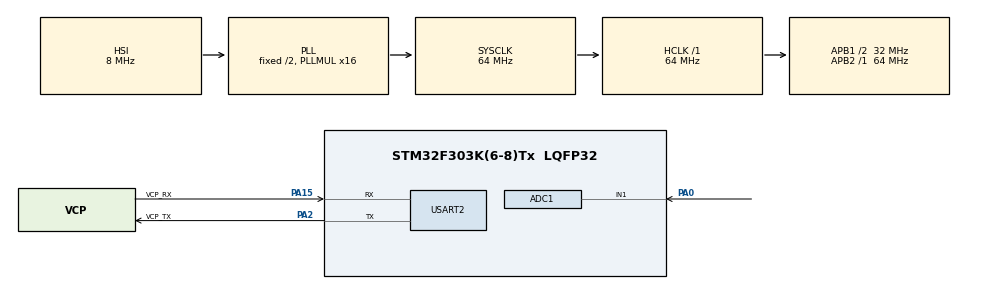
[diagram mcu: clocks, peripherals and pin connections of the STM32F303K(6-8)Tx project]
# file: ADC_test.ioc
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ADC1.Channel-5\#ChannelRegularConversion=ADC_CHANNEL_1
ADC1.ClockPrescaler=ADC_CLOCK_SYNC_PCLK_DIV4
ADC1.NbrOfConversionFlag=1
ADC1.Offset-5\#ChannelRegularConversion=0
ADC1.OffsetNumber-5\#ChannelRegularConversion=ADC_OFFSET_NONE
ADC1.Rank-5\#ChannelRegularConversion=1
ADC1.SamplingTime-5\#ChannelRegularConversion=ADC_SAMPLETIME_1CYCLE_5
ADC1.master=1
Mcu.Family=STM32F3
Mcu.Name=STM32F303K(6-8)Tx
Mcu.Package=LQFP32
NVIC.PriorityGroup=NVIC_PRIORITYGROUP_4
PA0.Mode=IN1-Single-Ended
PA0.Signal=ADC1_IN1
PA13.GPIO_Label=SWDIO
PA13.Mode=Serial_Wire
PA13.Signal=SYS_JTMS-SWDIO
PA14.GPIO_Label=SWCLK
PA14.Mode=Serial_Wire
PA14.Signal=SYS_JTCK-SWCLK
PA15.GPIO_Label=VCP_RX
PA15.Mode=Asynchronous
PA15.Signal=USART2_RX
PA2.GPIO_Label=VCP_TX
PA2.Mode=Asynchronous
PA2.Signal=USART2_TX
PF0\ /\ OSC_IN.GPIO_Label=MCO
PF0\ /\ OSC_IN.Mode=HSE-External-Clock-Source
PF0\ /\ OSC_IN.Signal=RCC_OSC_IN
ProjectManager.HeapSize=0x200
ProjectManager.StackSize=0x400
ProjectManager.TargetToolchain=TrueSTUDIO
RCC.AHBFreq_Value=64000000
RCC.APB1CLKDivider=RCC_HCLK_DIV2
RCC.APB1Freq_Value=32000000
RCC.APB1TimFreq_Value=64000000
RCC.APB2Freq_Value=64000000
RCC.APB2TimFreq_Value=64000000
RCC.CortexFreq_Value=64000000
RCC.HCLKFreq_Value=64000000
RCC.HSE_VALUE=8000000
RCC.HSI_VALUE=8000000
RCC.PLLMUL=RCC_PLL_MUL16
RCC.SYSCLKFreq_VALUE=64000000
RCC.SYSCLKSourceVirtual=RCC_SYSCLKSOURCE_PLLCLK
USART2.VirtualMode-Asynchronous=VM_ASYNC
board=NUCLEO-F303K8

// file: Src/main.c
/* USER CODE BEGIN Header */
/**
  ******************************************************************************
  * @file           : main.c
  * @brief          : Main program body
  ******************************************************************************
  ** This notice applies to any and all portions of this file
  * that are not between comment pairs USER CODE BEGIN and
  * USER CODE END. Other portions of this file, whether
  * inserted by the user or by software development tools
  * are owned by their respective copyright owners.
  *
  * COPYRIGHT(c) 2019 STMicroelectronics
  *
  * Redistribution and use in source and binary forms, with or without modification,
  * are permitted provided that the following conditions are met:
  *   1. Redistributions of source code must retain the above copyright notice,
  *      this list of conditions and the following disclaimer.
  *   2. Redistributions in binary form must reproduce the above copyright notice,
  *      this list of conditions and the following disclaimer in the documentation
  *      and/or other materials provided with the distribution.
  *   3. Neither the name of STMicroelectronics nor the names of its contributors
  *      may be used to endorse or promote products derived from this software
  *      without specific prior written permission.
  *
  * THIS SOFTWARE IS PROVIDED BY THE COPYRIGHT HOLDERS AND CONTRIBUTORS "AS IS"
  * AND ANY EXPRESS OR IMPLIED WARRANTIES, INCLUDING, BUT NOT LIMITED TO, THE
  * IMPLIED WARRANTIES OF MERCHANTABILITY AND FITNESS FOR A PARTICULAR PURPOSE ARE
  * DISCLAIMED. IN NO EVENT SHALL THE COPYRIGHT HOLDER OR CONTRIBUTORS BE LIABLE
  * FOR ANY DIRECT, INDIRECT, INCIDENTAL, SPECIAL, EXEMPLARY, OR CONSEQUENTIAL
  * DAMAGES (INCLUDING, BUT NOT LIMITED TO, PROCUREMENT OF SUBSTITUTE GOODS OR
  * SERVICES; LOSS OF USE, DATA, OR PROFITS; OR BUSINESS INTERRUPTION) HOWEVER
  * CAUSED AND ON ANY THEORY OF LIABILITY, WHETHER IN CONTRACT, STRICT LIABILITY,
  * OR TORT (INCLUDING NEGLIGENCE OR OTHERWISE) ARISING IN ANY WAY OUT OF THE USE
  * OF THIS SOFTWARE, EVEN IF ADVISED OF THE POSSIBILITY OF SUCH DAMAGE.
  *
  ******************************************************************************
  */
/* USER CODE END Header */

#include "main.h"

ADC_HandleTypeDef hadc1;

UART_HandleTypeDef huart2;

void SystemClock_Config(void);
static void MX_GPIO_Init(void);
static void MX_USART2_UART_Init(void);
static void MX_ADC1_Init(void);

int main(void)
{

  /* MCU Configuration--------------------------------------------------------*/

  /* Reset of all peripherals, Initializes the Flash interface and the Systick. */
  HAL_Init();

  /* Configure the system clock */
  SystemClock_Config();

  /* Initialize all configured peripherals */
  MX_GPIO_Init();
  MX_USART2_UART_Init();
  MX_ADC1_Init();
  /* USER CODE BEGIN 2 */
  int data_adc;
  /* USER CODE END 2 */

  /* Infinite loop */
  while (1)
  {
	  HAL_ADC_Start(&hadc1);
	  HAL_ADC_PollForConversion(&hadc1, 1000);
	  data_adc = HAL_ADC_GetValue(&hadc1);
	  HAL_ADC_Stop(&hadc1);

	  tx_UART_int(&huart2, data_adc, 4, 10);

	  HAL_Delay(100);
  }
}

void SystemClock_Config(void)
{
  RCC_OscInitTypeDef RCC_OscInitStruct = {0};
  RCC_ClkInitTypeDef RCC_ClkInitStruct = {0};

  /**Initializes the CPU, AHB and APB busses clocks
  */
  RCC_OscInitStruct.OscillatorType = RCC_OSCILLATORTYPE_HSI;
  RCC_OscInitStruct.HSIState = RCC_HSI_ON;
  RCC_OscInitStruct.HSICalibrationValue = RCC_HSICALIBRATION_DEFAULT;
  RCC_OscInitStruct.PLL.PLLState = RCC_PLL_ON;
  RCC_OscInitStruct.PLL.PLLSource = RCC_PLLSOURCE_HSI;
  RCC_OscInitStruct.PLL.PLLMUL = RCC_PLL_MUL16;
  if (HAL_RCC_OscConfig(&RCC_OscInitStruct) != HAL_OK)
  {
    Error_Handler();
  }
  /**Initializes the CPU, AHB and APB busses clocks
  */
  RCC_ClkInitStruct.ClockType = RCC_CLOCKTYPE_HCLK|RCC_CLOCKTYPE_SYSCLK
                              |RCC_CLOCKTYPE_PCLK1|RCC_CLOCKTYPE_PCLK2;
  RCC_ClkInitStruct.SYSCLKSource = RCC_SYSCLKSOURCE_PLLCLK;
  RCC_ClkInitStruct.AHBCLKDivider = RCC_SYSCLK_DIV1;
  RCC_ClkInitStruct.APB1CLKDivider = RCC_HCLK_DIV2;
  RCC_ClkInitStruct.APB2CLKDivider = RCC_HCLK_DIV1;

  if (HAL_RCC_ClockConfig(&RCC_ClkInitStruct, FLASH_LATENCY_2) != HAL_OK)
  {
    Error_Handler();
  }
}

static void MX_ADC1_Init(void)
{

  ADC_MultiModeTypeDef multimode = {0};
  ADC_ChannelConfTypeDef sConfig = {0};

  /**Common config
  */
  hadc1.Instance = ADC1;
  hadc1.Init.ClockPrescaler = ADC_CLOCK_SYNC_PCLK_DIV4;
  hadc1.Init.Resolution = ADC_RESOLUTION_12B;
  hadc1.Init.ScanConvMode = ADC_SCAN_DISABLE;
  hadc1.Init.ContinuousConvMode = DISABLE;
  hadc1.Init.DiscontinuousConvMode = DISABLE;
  hadc1.Init.ExternalTrigConvEdge = ADC_EXTERNALTRIGCONVEDGE_NONE;
  hadc1.Init.ExternalTrigConv = ADC_SOFTWARE_START;
  hadc1.Init.DataAlign = ADC_DATAALIGN_RIGHT;
  hadc1.Init.NbrOfConversion = 1;
  hadc1.Init.DMAContinuousRequests = DISABLE;
  hadc1.Init.EOCSelection = ADC_EOC_SINGLE_CONV;
  hadc1.Init.LowPowerAutoWait = DISABLE;
  hadc1.Init.Overrun = ADC_OVR_DATA_OVERWRITTEN;
  if (HAL_ADC_Init(&hadc1) != HAL_OK)
  {
    Error_Handler();
  }
  /**Configure the ADC multi-mode
  */
  multimode.Mode = ADC_MODE_INDEPENDENT;
  if (HAL_ADCEx_MultiModeConfigChannel(&hadc1, &multimode) != HAL_OK)
  {
    Error_Handler();
  }
  /**Configure Regular Channel
  */
  sConfig.Channel = ADC_CHANNEL_1;
  sConfig.Rank = ADC_REGULAR_RANK_1;
  sConfig.SingleDiff = ADC_SINGLE_ENDED;
  sConfig.SamplingTime = ADC_SAMPLETIME_1CYCLE_5;
  sConfig.OffsetNumber = ADC_OFFSET_NONE;
  sConfig.Offset = 0;
  if (HAL_ADC_ConfigChannel(&hadc1, &sConfig) != HAL_OK)
  {
    Error_Handler();
  }

}

static void MX_USART2_UART_Init(void)
{

  huart2.Instance = USART2;
  huart2.Init.BaudRate = 38400;
  huart2.Init.WordLength = UART_WORDLENGTH_8B;
  huart2.Init.StopBits = UART_STOPBITS_1;
  huart2.Init.Parity = UART_PARITY_NONE;
  huart2.Init.Mode = UART_MODE_TX_RX;
  huart2.Init.HwFlowCtl = UART_HWCONTROL_NONE;
  huart2.Init.OverSampling = UART_OVERSAMPLING_16;
  huart2.Init.OneBitSampling = UART_ONE_BIT_SAMPLE_DISABLE;
  huart2.AdvancedInit.AdvFeatureInit = UART_ADVFEATURE_NO_INIT;
  if (HAL_UART_Init(&huart2) != HAL_OK)
  {
    Error_Handler();
  }

}

static void MX_GPIO_Init(void)
{

  /* GPIO Ports Clock Enable */
  __HAL_RCC_GPIOF_CLK_ENABLE();
  __HAL_RCC_GPIOA_CLK_ENABLE();

}

/* USER CODE BEGIN 4 */
void tx_UART_int(UART_HandleTypeDef *huart, int data, uint16_t Size, uint32_t Timeout)
{
	char data_char[Size+2];		// String de chars
	uint8_t data_tx[Size+2];	// String de uint8_t
	uint8_t i;

	sprintf(data_char,"%d\r\n", data);	// Cada numero del int en un char

	for(i=0; i<Size+2; i++ ) {			// Casting de char a uint8_t
		data_tx[i] = (uint8_t) data_char[i];
	}
	HAL_UART_Transmit(huart,data_tx,sizeof(data_tx), 10);	// TX por UART del array de uint8_t
}
/* USER CODE END 4 */

void Error_Handler(void)
{
}

/************************ (C) COPYRIGHT STMicroelectronics *****END OF FILE****/
